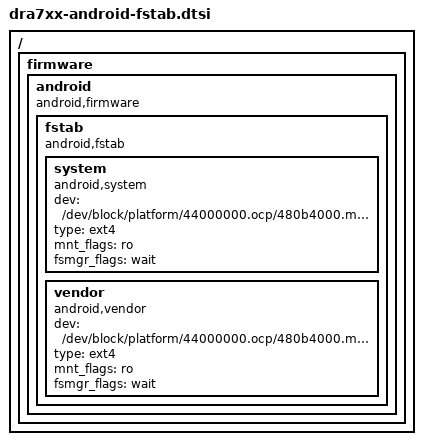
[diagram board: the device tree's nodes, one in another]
/*
 * Copyright (C) 2017 Texas Instruments Incorporated - http://www.ti.com/
 *
 * This program is free software; you can redistribute it and/or modify
 * it under the terms of the GNU General Public License version 2 as
 * published by the Free Software Foundation.
 */

/ {
	firmware {
		android {
			compatible = "android,firmware";
			fstab {
				compatible = "android,fstab";
				system {
					compatible = "android,system";
					dev = "/dev/block/platform/44000000.ocp/480b4000.mmc/by-name/system";
					type = "ext4";
					mnt_flags = "ro";
					fsmgr_flags = "wait";
				};
				vendor {
					compatible = "android,vendor";
					dev = "/dev/block/platform/44000000.ocp/480b4000.mmc/by-name/vendor";
					type = "ext4";
					mnt_flags = "ro";
					fsmgr_flags = "wait";
				};
			};
		};
	};
};
